# ISD9300_v3 register map
File version: 1.0
Registers are 32-bit, read-write, reset 0x0 unless marked. A register's access mark holds for its fields unless they carry their own. Offsets are from the block's base; [hi:lo] are bit positions; <NAME> marks a mode.

## WDT — WDT Register Map
Base 0x40004000
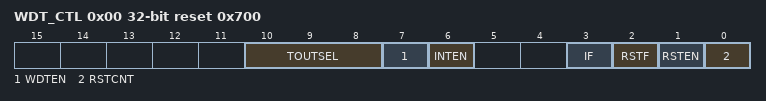
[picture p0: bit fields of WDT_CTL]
0x00 WDT_CTL reset 0x700 — Watchdog Timer Control Register
  [10:8] TOUTSEL — Watchdog Timer Interval Select. These three bits select the timeout interval for the Watchdog timer, a watchdog reset will occur 1024 clock cycles later if WDG not reset. The timeout is given by: Interrupt Timeout aaa 2^(2xTOUTSEL+4) x WDT_CLK. Reset Timeout aaa (2^(2xTOUTSEL+4) +1024) x WDT_CLK. Where WDT_CLK is the period of the Watchdog Timer clock source.
  [7] WDTEN — Watchdog Timer Enable
    0=Disable the Watchdog timer (This action will reset the internal counter); 1=Enable the Watchdog timer
  [6] INTEN — Watchdog Timer Interrupt Enable
    0=Disable the Watchdog timer interrupt; 1=Enable the Watchdog timer interrupt
  [3] IF — Watchdog Timer Interrupt Flag. If the Watchdog timer interrupt is enabled, then the hardware will set this bit to indicate that the Watchdog timer interrupt has occurred. If the Watchdog timer interrupt is not enabled, then this bit indicates that a timeout period has elapsed. NOTE: This bit is cleared by writing 1 to this bit.
    0=Watchdog timer interrupt has not occurred; 1=Watchdog timer interrupt has occurred
  [2] RSTF — Watchdog Timer Reset Flag. When the Watchdog timer initiates a reset, the hardware will set this bit. This flag can be read by software to determine the source of reset. Software is responsible to clear it manually by writing 1 to it. If RSTEN is disabled, then the Watchdog timer has no effect on this bit. NOTE: This bit is cleared by writing 1 to this bit.
    0=Watchdog timer reset has not occurred; 1=Watchdog timer reset has occurred
  [1] RSTEN — Watchdog Timer Reset Enable. Setting this bit will enable the Watchdog timer reset function.
    0=Disable Watchdog timer reset function; 1=Enable Watchdog timer reset function
  [0] RSTCNT — Clear Watchdog Timer. Set this bit will clear the Watchdog timer. NOTE: This bit will auto clear after few clock cycle
    0=Writing 0 to this bit has no effect; 1=Reset the contents of the Watchdog timer

## FMC — FMC Register Map
Base 0x5000C000
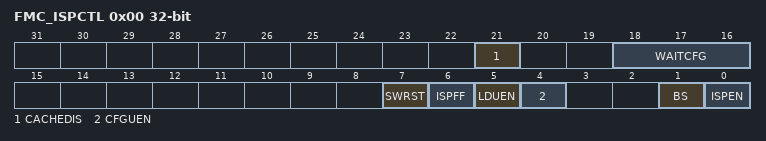
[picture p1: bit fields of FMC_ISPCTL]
0x00 FMC_ISPCTL — ISP Control Register
  [21] CACHEDIS — Cache Disable. When set to 1, caching of flash memory reads is disabled.
  [18:16] WAITCFG — Flash Access Wait State Configuration. For M and H speed grade parts this sets the access speed to the flash memory. 0x00: Three wait states. HCLK > 72MHz. 0x01: Two wait states. 72MHz > HCLK > 50MHz. 0x02: One wait state. HCLK <aaa 50MHz. Before changing WAITCFG, ensure HCLK speed is < 50MHz.
  [7] SWRST — Software Reset. Writing 1 to this bit will initiate a software reset. It is cleared by hardware after reset.
  [6] ISPFF — ISP Fail Flag. This bit is set by hardware when a triggered ISP meets any of the following conditions: (1) APROM writes to itself. (2) LDROM writes to itself. (3) Destination address is illegal, such as over an available range. Write 1 to clear.
  [5] LDUEN — LDROM Update Enable. LDROM update enable bit.
    0=LDROM cannot be updated; 1=LDROM can be updated when the MCU runs in APROM
  [4] CFGUEN — CONFIG Update Enable. When enabled, ISP functions can access the CONFIG address space and modify device configuration area.
    0=Disable; 1=Enable
  [1] BS — Boot Select. Modify this bit to select which ROM next boot is to occur. This bit also functions as MCU boot status flag, which can be used to check where MCU booted from. This bit is initialized after power-on reset with the inverse of CBS in Config0; It is not reset for any other reset event.
    0=APROM; 1=LDROM
  [0] ISPEN — ISP Enable
    0=Disable ISP function; 1=Enable ISP function
0x04 FMC_ISPADDR — ISP Address Register
  [31:0] ISPADDR — ISP Address Register. This is the memory address register that a subsequent ISP command will access. ISP operation are carried out on 32bit words only, consequently ISPADDR [1:0] must be 00b for correct ISP operation.
0x08 FMC_ISPDAT — ISP Data Register
  [31:0] ISPDAT — ISP Data Register. Write data to this register before an ISP program operation. Read data from this register after an ISP read operation
0x0C FMC_ISPCMD — ISP Command Register
  [5:0] CMD — ISP Command. Operation Mode : CMD. Standby : 0x3X. Read : 0x00. Program : 0x21. Page Erase : 0x22. Read CID : 0x0B. Read DID : 0x0C
0x10 FMC_ISPTRG — ISP Trigger Control Register
  [0] ISPGO — ISP Start Trigger. Write 1 to start ISP operation. This will be cleared to 0 by hardware automatically when ISP operation is finished. After triggering an ISP function M0 instruction pipeline should be flushed with a ISB instruction to guarantee data integrity. This is a protected register, user must first follow the unlock sequence (see Protected Register Lock Key Register (SYS_REGLCTL)) to gain access.
    0=ISP operation is finished; 1=ISP is on going
0x14 FMC_DFBA ro reset not defined — Data Flash Base Address
  [31:0] DFBA — Data Flash Base Address. This register reports the data flash starting address. It is a read only register. Data flash size is defined by user configuration; register content is loaded from Config1 when chip is reset.
